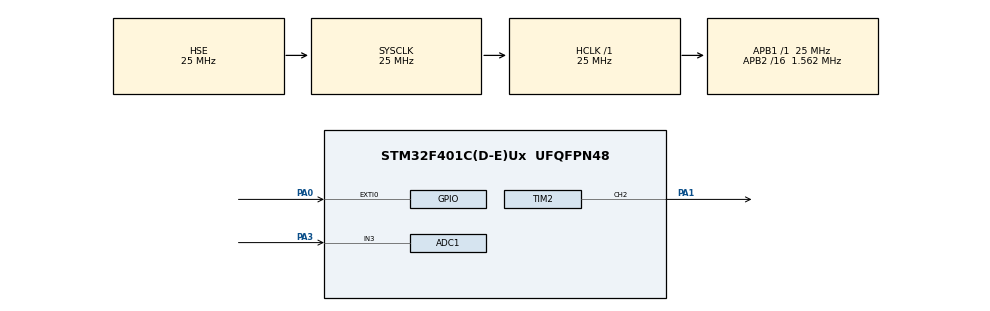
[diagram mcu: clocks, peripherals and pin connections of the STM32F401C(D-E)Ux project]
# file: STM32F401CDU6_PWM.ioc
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ADC1.Channel-2\#ChannelRegularConversion=ADC_CHANNEL_3
ADC1.ClockPrescaler=ADC_CLOCK_SYNC_PCLK_DIV2
ADC1.ContinuousConvMode=ENABLE
ADC1.DMAContinuousRequests=ENABLE
ADC1.NbrOfConversionFlag=1
ADC1.Rank-2\#ChannelRegularConversion=1
ADC1.SamplingTime-2\#ChannelRegularConversion=ADC_SAMPLETIME_480CYCLES
ADC1.master=1
Dma.ADC1.0.Direction=DMA_PERIPH_TO_MEMORY
Dma.ADC1.0.FIFOMode=DMA_FIFOMODE_DISABLE
Dma.ADC1.0.Instance=DMA2_Stream0
Dma.ADC1.0.MemDataAlignment=DMA_MDATAALIGN_HALFWORD
Dma.ADC1.0.MemInc=DMA_MINC_ENABLE
Dma.ADC1.0.Mode=DMA_CIRCULAR
Dma.ADC1.0.PeriphDataAlignment=DMA_PDATAALIGN_HALFWORD
Dma.ADC1.0.PeriphInc=DMA_PINC_DISABLE
Dma.ADC1.0.Priority=DMA_PRIORITY_LOW
Dma.Request0=ADC1
Mcu.Family=STM32F4
Mcu.Name=STM32F401C(D-E)Ux
Mcu.Package=UFQFPN48
NVIC.DMA2_Stream0_IRQn=true\:0\:0\:false\:false\:true\:false\:true\:true
NVIC.EXTI0_IRQn=true\:0\:0\:false\:false\:true\:true\:true\:true
NVIC.PriorityGroup=NVIC_PRIORITYGROUP_4
PA0-WKUP.GPIO_PuPd=GPIO_PULLDOWN
PA0-WKUP.Signal=GPXTI0
PA1.Signal=S_TIM2_CH2
PA3.Signal=ADCx_IN3
PH0\ -\ OSC_IN.Mode=HSE-External-Oscillator
PH0\ -\ OSC_IN.Signal=RCC_OSC_IN
PH1\ -\ OSC_OUT.Mode=HSE-External-Oscillator
PH1\ -\ OSC_OUT.Signal=RCC_OSC_OUT
ProjectManager.HeapSize=0x200
ProjectManager.StackSize=0x400
ProjectManager.TargetToolchain=STM32CubeIDE
RCC.48MHZClocksFreq_Value=48000000
RCC.AHBFreq_Value=25000000
RCC.APB1Freq_Value=25000000
RCC.APB1TimFreq_Value=25000000
RCC.APB2CLKDivider=RCC_HCLK_DIV16
RCC.APB2Freq_Value=1562500
RCC.APB2TimFreq_Value=3125000
RCC.CortexFreq_Value=25000000
RCC.HCLKFreq_Value=25000000
RCC.HSE_VALUE=25000000
RCC.HSI_VALUE=16000000
RCC.LSE_VALUE=32768
RCC.SYSCLKFreq_VALUE=25000000
RCC.SYSCLKSource=RCC_SYSCLKSOURCE_HSE
RCC.VCOOutputFreq_Value=192000000
SH.ADCx_IN3.0=ADC1_IN3,IN3
SH.S_TIM2_CH2.0=TIM2_CH2,PWM Generation2 CH2
TIM2.AutoReloadPreload=TIM_AUTORELOAD_PRELOAD_ENABLE
TIM2.Channel-PWM\ Generation2\ CH2=TIM_CHANNEL_2
TIM2.Period=500-1
TIM2.Prescaler=25000-1
VP_TIM2_VS_ClockSourceINT.Mode=Internal
board=custom

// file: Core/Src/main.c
/* USER CODE BEGIN Header */
/**
  ******************************************************************************
  * @file           : main.c
  * @brief          : Main program body
  ******************************************************************************
  * @attention
  *
  * Copyright (c) 2024 STMicroelectronics.
  * All rights reserved.
  *
  * This software is licensed under terms that can be found in the LICENSE file
  * in the root directory of this software component.
  * If no LICENSE file comes with this software, it is provided AS-IS.
  *
  ******************************************************************************
  */
/* USER CODE END Header */
#include "main.h"

ADC_HandleTypeDef hadc1;
DMA_HandleTypeDef hdma_adc1;

TIM_HandleTypeDef htim2;

/* USER CODE BEGIN PV */
HAL_StatusTypeDef htim2_status;
static uint32_t buffer[1586*10];
/* USER CODE END PV */

void SystemClock_Config(void);
static void MX_GPIO_Init(void);
static void MX_DMA_Init(void);
static void MX_TIM2_Init(void);
static void MX_ADC1_Init(void);

int main(void)
{

  /* MCU Configuration--------------------------------------------------------*/

  /* Reset of all peripherals, Initializes the Flash interface and the Systick. */
  HAL_Init();

  /* Configure the system clock */
  SystemClock_Config();

  /* Initialize all configured peripherals */
  MX_GPIO_Init();
  MX_DMA_Init();
  MX_TIM2_Init();
  MX_ADC1_Init();
  /* USER CODE BEGIN 2 */
  HAL_ADC_Start_DMA(&hadc1,(uint32_t*)&buffer , 1000);
  /* Start PWM signal generation on TIM2 Channel 2 */
  htim2_status = HAL_TIM_PWM_Start(&htim2, TIM_CHANNEL_2);
  __HAL_TIM_SET_COMPARE(&htim2, TIM_CHANNEL_2, 50); // Set duty cycle to 75%
  HAL_Delay(5000);
  htim2_status = HAL_TIM_PWM_Stop(&htim2, TIM_CHANNEL_2);
  /* USER CODE END 2 */

  /* Infinite loop */
  while (1)
  {

  }
}

void SystemClock_Config(void)
{
  RCC_OscInitTypeDef RCC_OscInitStruct = {0};
  RCC_ClkInitTypeDef RCC_ClkInitStruct = {0};

  /** Configure the main internal regulator output voltage
  */
  __HAL_RCC_PWR_CLK_ENABLE();
  __HAL_PWR_VOLTAGESCALING_CONFIG(PWR_REGULATOR_VOLTAGE_SCALE2);

  /** Initializes the RCC Oscillators according to the specified parameters
  * in the RCC_OscInitTypeDef structure.
  */
  RCC_OscInitStruct.OscillatorType = RCC_OSCILLATORTYPE_HSE;
  RCC_OscInitStruct.HSEState = RCC_HSE_ON;
  RCC_OscInitStruct.PLL.PLLState = RCC_PLL_NONE;
  if (HAL_RCC_OscConfig(&RCC_OscInitStruct) != HAL_OK)
  {
    Error_Handler();
  }

  /** Initializes the CPU, AHB and APB buses clocks
  */
  RCC_ClkInitStruct.ClockType = RCC_CLOCKTYPE_HCLK|RCC_CLOCKTYPE_SYSCLK
                              |RCC_CLOCKTYPE_PCLK1|RCC_CLOCKTYPE_PCLK2;
  RCC_ClkInitStruct.SYSCLKSource = RCC_SYSCLKSOURCE_HSE;
  RCC_ClkInitStruct.AHBCLKDivider = RCC_SYSCLK_DIV1;
  RCC_ClkInitStruct.APB1CLKDivider = RCC_HCLK_DIV1;
  RCC_ClkInitStruct.APB2CLKDivider = RCC_HCLK_DIV16;

  if (HAL_RCC_ClockConfig(&RCC_ClkInitStruct, FLASH_LATENCY_0) != HAL_OK)
  {
    Error_Handler();
  }
}

static void MX_ADC1_Init(void)
{

  ADC_ChannelConfTypeDef sConfig = {0};

  /** Configure the global features of the ADC (Clock, Resolution, Data Alignment and number of conversion)
  */
  hadc1.Instance = ADC1;
  hadc1.Init.ClockPrescaler = ADC_CLOCK_SYNC_PCLK_DIV2;
  hadc1.Init.Resolution = ADC_RESOLUTION_12B;
  hadc1.Init.ScanConvMode = DISABLE;
  hadc1.Init.ContinuousConvMode = ENABLE;
  hadc1.Init.DiscontinuousConvMode = DISABLE;
  hadc1.Init.ExternalTrigConvEdge = ADC_EXTERNALTRIGCONVEDGE_NONE;
  hadc1.Init.ExternalTrigConv = ADC_SOFTWARE_START;
  hadc1.Init.DataAlign = ADC_DATAALIGN_RIGHT;
  hadc1.Init.NbrOfConversion = 1;
  hadc1.Init.DMAContinuousRequests = ENABLE;
  hadc1.Init.EOCSelection = ADC_EOC_SINGLE_CONV;
  if (HAL_ADC_Init(&hadc1) != HAL_OK)
  {
    Error_Handler();
  }

  /** Configure for the selected ADC regular channel its corresponding rank in the sequencer and its sample time.
  */
  sConfig.Channel = ADC_CHANNEL_3;
  sConfig.Rank = 1;
  sConfig.SamplingTime = ADC_SAMPLETIME_480CYCLES;
  if (HAL_ADC_ConfigChannel(&hadc1, &sConfig) != HAL_OK)
  {
    Error_Handler();
  }

}

static void MX_TIM2_Init(void)
{

  TIM_ClockConfigTypeDef sClockSourceConfig = {0};
  TIM_MasterConfigTypeDef sMasterConfig = {0};
  TIM_OC_InitTypeDef sConfigOC = {0};

  htim2.Instance = TIM2;
  htim2.Init.Prescaler = 25000-1;
  htim2.Init.CounterMode = TIM_COUNTERMODE_UP;
  htim2.Init.Period = 500-1;
  htim2.Init.ClockDivision = TIM_CLOCKDIVISION_DIV1;
  htim2.Init.AutoReloadPreload = TIM_AUTORELOAD_PRELOAD_ENABLE;
  if (HAL_TIM_Base_Init(&htim2) != HAL_OK)
  {
    Error_Handler();
  }
  sClockSourceConfig.ClockSource = TIM_CLOCKSOURCE_INTERNAL;
  if (HAL_TIM_ConfigClockSource(&htim2, &sClockSourceConfig) != HAL_OK)
  {
    Error_Handler();
  }
  if (HAL_TIM_PWM_Init(&htim2) != HAL_OK)
  {
    Error_Handler();
  }
  sMasterConfig.MasterOutputTrigger = TIM_TRGO_RESET;
  sMasterConfig.MasterSlaveMode = TIM_MASTERSLAVEMODE_DISABLE;
  if (HAL_TIMEx_MasterConfigSynchronization(&htim2, &sMasterConfig) != HAL_OK)
  {
    Error_Handler();
  }
  sConfigOC.OCMode = TIM_OCMODE_PWM1;
  sConfigOC.Pulse = 0;
  sConfigOC.OCPolarity = TIM_OCPOLARITY_HIGH;
  sConfigOC.OCFastMode = TIM_OCFAST_DISABLE;
  if (HAL_TIM_PWM_ConfigChannel(&htim2, &sConfigOC, TIM_CHANNEL_2) != HAL_OK)
  {
    Error_Handler();
  }
  HAL_TIM_MspPostInit(&htim2);

}

static void MX_DMA_Init(void)
{

  /* DMA controller clock enable */
  __HAL_RCC_DMA2_CLK_ENABLE();

  /* DMA interrupt init */
  /* DMA2_Stream0_IRQn interrupt configuration */
  HAL_NVIC_SetPriority(DMA2_Stream0_IRQn, 0, 0);
  HAL_NVIC_EnableIRQ(DMA2_Stream0_IRQn);

}

static void MX_GPIO_Init(void)
{
  GPIO_InitTypeDef GPIO_InitStruct = {0};

  /* GPIO Ports Clock Enable */
  __HAL_RCC_GPIOH_CLK_ENABLE();
  __HAL_RCC_GPIOA_CLK_ENABLE();

  /*Configure GPIO pin : PA0 */
  GPIO_InitStruct.Pin = GPIO_PIN_0;
  GPIO_InitStruct.Mode = GPIO_MODE_IT_RISING;
  GPIO_InitStruct.Pull = GPIO_PULLDOWN;
  HAL_GPIO_Init(GPIOA, &GPIO_InitStruct);

  /* EXTI interrupt init*/
  HAL_NVIC_SetPriority(EXTI0_IRQn, 0, 0);
  HAL_NVIC_EnableIRQ(EXTI0_IRQn);

}

/* USER CODE BEGIN 4 */
/* HAL callback function for EXTI line 0 (PA0) */
void HAL_GPIO_EXTI_Callback(uint16_t GPIO_Pin) {
    if (GPIO_Pin == GPIO_PIN_0) {
    	if(htim2_status == HAL_OK)
    	{
    		htim2_status = HAL_TIM_PWM_Start(&htim2, TIM_CHANNEL_2);
    	}
    	else{
    		htim2_status = HAL_TIM_PWM_Stop(&htim2, TIM_CHANNEL_2);
    	}
    }
}

void HAL_ADC_ConvHalfCpltCallback(ADC_HandleTypeDef * hadc)
{
	__HAL_TIM_SET_COMPARE(&htim2, TIM_CHANNEL_2, 100);
}

void HAL_ADC_ConvCpltCallback(ADC_HandleTypeDef * hadc)
{
	__HAL_TIM_SET_COMPARE(&htim2, TIM_CHANNEL_2, 0);
}
/* USER CODE END 4 */

void Error_Handler(void)
{
  __disable_irq();
  while (1)
  {
  }
}
